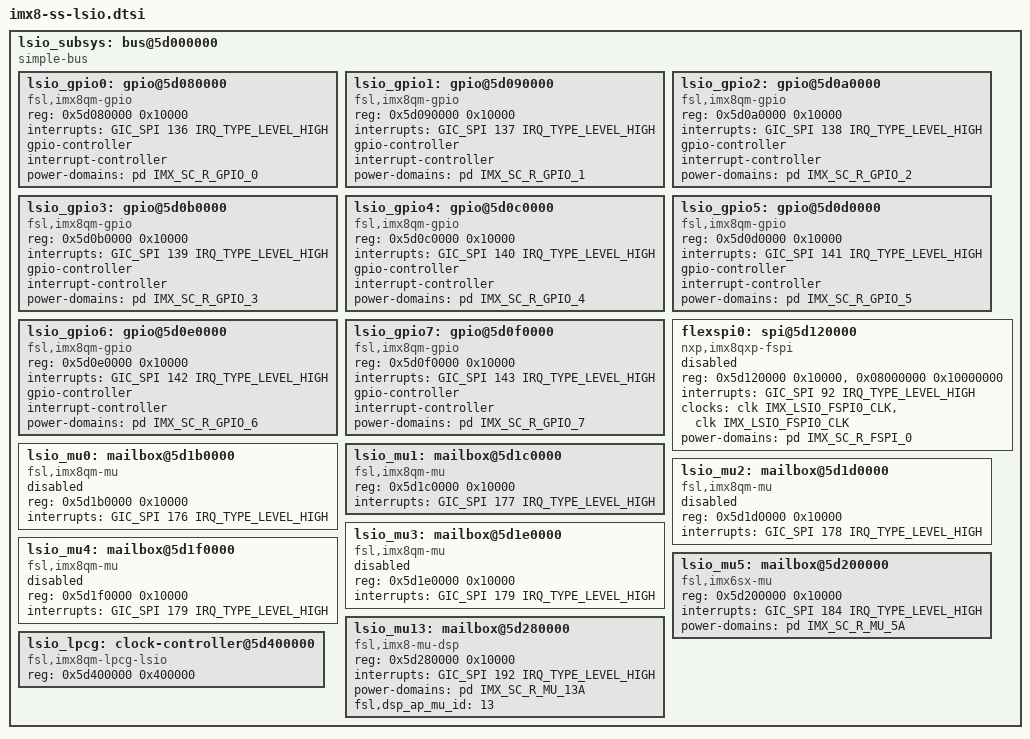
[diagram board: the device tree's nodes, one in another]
// SPDX-License-Identifier: GPL-2.0+
/*
 * Copyright 2018 NXP
 *	Dong Aisheng <aisheng.dong@nxp.com>
 */

lsio_subsys: bus@5d000000 {
	compatible = "simple-bus";
	#address-cells = <1>;
	#size-cells = <1>;
	ranges = <0x5d000000 0x0 0x5d000000 0x1000000>,
		 <0x08000000 0x0 0x08000000 0x10000000>;

	lsio_gpio0: gpio@5d080000 {
		compatible = "fsl,imx8qm-gpio", "fsl,imx35-gpio";
		reg = <0x5d080000 0x10000>;
		interrupts = <GIC_SPI 136 IRQ_TYPE_LEVEL_HIGH>;
		gpio-controller;
		#gpio-cells = <2>;
		interrupt-controller;
		#interrupt-cells = <2>;
		power-domains = <&pd IMX_SC_R_GPIO_0>;
	};

	lsio_gpio1: gpio@5d090000 {
		compatible = "fsl,imx8qm-gpio", "fsl,imx35-gpio";
		reg = <0x5d090000 0x10000>;
		interrupts = <GIC_SPI 137 IRQ_TYPE_LEVEL_HIGH>;
		gpio-controller;
		#gpio-cells = <2>;
		interrupt-controller;
		#interrupt-cells = <2>;
		power-domains = <&pd IMX_SC_R_GPIO_1>;
	};

	lsio_gpio2: gpio@5d0a0000 {
		compatible = "fsl,imx8qm-gpio", "fsl,imx35-gpio";
		reg = <0x5d0a0000 0x10000>;
		interrupts = <GIC_SPI 138 IRQ_TYPE_LEVEL_HIGH>;
		gpio-controller;
		#gpio-cells = <2>;
		interrupt-controller;
		#interrupt-cells = <2>;
		power-domains = <&pd IMX_SC_R_GPIO_2>;
	};

	lsio_gpio3: gpio@5d0b0000 {
		compatible = "fsl,imx8qm-gpio", "fsl,imx35-gpio";
		reg = <0x5d0b0000 0x10000>;
		interrupts = <GIC_SPI 139 IRQ_TYPE_LEVEL_HIGH>;
		gpio-controller;
		#gpio-cells = <2>;
		interrupt-controller;
		#interrupt-cells = <2>;
		power-domains = <&pd IMX_SC_R_GPIO_3>;
	};

	lsio_gpio4: gpio@5d0c0000 {
		compatible = "fsl,imx8qm-gpio", "fsl,imx35-gpio";
		reg = <0x5d0c0000 0x10000>;
		interrupts = <GIC_SPI 140 IRQ_TYPE_LEVEL_HIGH>;
		gpio-controller;
		#gpio-cells = <2>;
		interrupt-controller;
		#interrupt-cells = <2>;
		power-domains = <&pd IMX_SC_R_GPIO_4>;
	};

	lsio_gpio5: gpio@5d0d0000 {
		compatible = "fsl,imx8qm-gpio", "fsl,imx35-gpio";
		reg = <0x5d0d0000 0x10000>;
		interrupts = <GIC_SPI 141 IRQ_TYPE_LEVEL_HIGH>;
		gpio-controller;
		#gpio-cells = <2>;
		interrupt-controller;
		#interrupt-cells = <2>;
		power-domains = <&pd IMX_SC_R_GPIO_5>;
	};

	lsio_gpio6: gpio@5d0e0000 {
		compatible = "fsl,imx8qm-gpio", "fsl,imx35-gpio";
		reg = <0x5d0e0000 0x10000>;
		interrupts = <GIC_SPI 142 IRQ_TYPE_LEVEL_HIGH>;
		gpio-controller;
		#gpio-cells = <2>;
		interrupt-controller;
		#interrupt-cells = <2>;
		power-domains = <&pd IMX_SC_R_GPIO_6>;
	};

	lsio_gpio7: gpio@5d0f0000 {
		compatible = "fsl,imx8qm-gpio", "fsl,imx35-gpio";
		reg = <0x5d0f0000 0x10000>;
		interrupts = <GIC_SPI 143 IRQ_TYPE_LEVEL_HIGH>;
		gpio-controller;
		#gpio-cells = <2>;
		interrupt-controller;
		#interrupt-cells = <2>;
		power-domains = <&pd IMX_SC_R_GPIO_7>;
	};

	flexspi0: spi@5d120000 {
		#address-cells = <1>;
		#size-cells = <0>;
		compatible = "nxp,imx8qxp-fspi";
		reg = <0x5d120000 0x10000>, <0x08000000 0x10000000>;
		reg-names = "fspi_base", "fspi_mmap";
		interrupts = <GIC_SPI 92 IRQ_TYPE_LEVEL_HIGH>;
		clocks = <&clk IMX_LSIO_FSPI0_CLK>,
			 <&clk IMX_LSIO_FSPI0_CLK>;
		clock-names = "fspi", "fspi_en";
		power-domains = <&pd IMX_SC_R_FSPI_0>;
		status = "disabled";
	};

	lsio_mu0: mailbox@5d1b0000 {
		compatible = "fsl,imx8qm-mu", "fsl,imx6sx-mu";
		reg = <0x5d1b0000 0x10000>;
		interrupts = <GIC_SPI 176 IRQ_TYPE_LEVEL_HIGH>;
		#mbox-cells = <0>;
		status = "disabled";
	};

	lsio_mu1: mailbox@5d1c0000 {
		compatible = "fsl,imx8qm-mu", "fsl,imx6sx-mu";
		reg = <0x5d1c0000 0x10000>;
		interrupts = <GIC_SPI 177 IRQ_TYPE_LEVEL_HIGH>;
		#mbox-cells = <2>;
	};

	lsio_mu2: mailbox@5d1d0000 {
		compatible = "fsl,imx8qm-mu", "fsl,imx6sx-mu";
		reg = <0x5d1d0000 0x10000>;
		interrupts = <GIC_SPI 178 IRQ_TYPE_LEVEL_HIGH>;
		#mbox-cells = <2>;
		status = "disabled";
	};

	lsio_mu3: mailbox@5d1e0000 {
		compatible = "fsl,imx8qm-mu", "fsl,imx6sx-mu";
		reg = <0x5d1e0000 0x10000>;
		interrupts = <GIC_SPI 179 IRQ_TYPE_LEVEL_HIGH>;
		#mbox-cells = <2>;
		status = "disabled";
	};

	lsio_mu4: mailbox@5d1f0000 {
		compatible = "fsl,imx8qm-mu", "fsl,imx6sx-mu";
		reg = <0x5d1f0000 0x10000>;
		interrupts = <GIC_SPI 179 IRQ_TYPE_LEVEL_HIGH>;
		#mbox-cells = <2>;
		status = "disabled";
	};

	lsio_mu5: mailbox@5d200000 {
		compatible = "fsl,imx6sx-mu";
		reg = <0x5d200000 0x10000>;
		interrupts = <GIC_SPI 184 IRQ_TYPE_LEVEL_HIGH>;
		#mbox-cells = <2>;
		power-domains = <&pd IMX_SC_R_MU_5A>;
	};

	lsio_mu13: mailbox@5d280000 {
		compatible = "fsl,imx8-mu-dsp", "fsl,imx6sx-mu";
		reg = <0x5d280000 0x10000>;
		interrupts = <GIC_SPI 192 IRQ_TYPE_LEVEL_HIGH>;
		#mbox-cells = <2>;
		power-domains = <&pd IMX_SC_R_MU_13A>;
		fsl,dsp_ap_mu_id = <13>;
	};

	lsio_lpcg: clock-controller@5d400000 {
		compatible = "fsl,imx8qm-lpcg-lsio", "fsl,imx8qxp-lpcg-lsio";
		reg = <0x5d400000 0x400000>;
		#clock-cells = <1>;
	};
};
